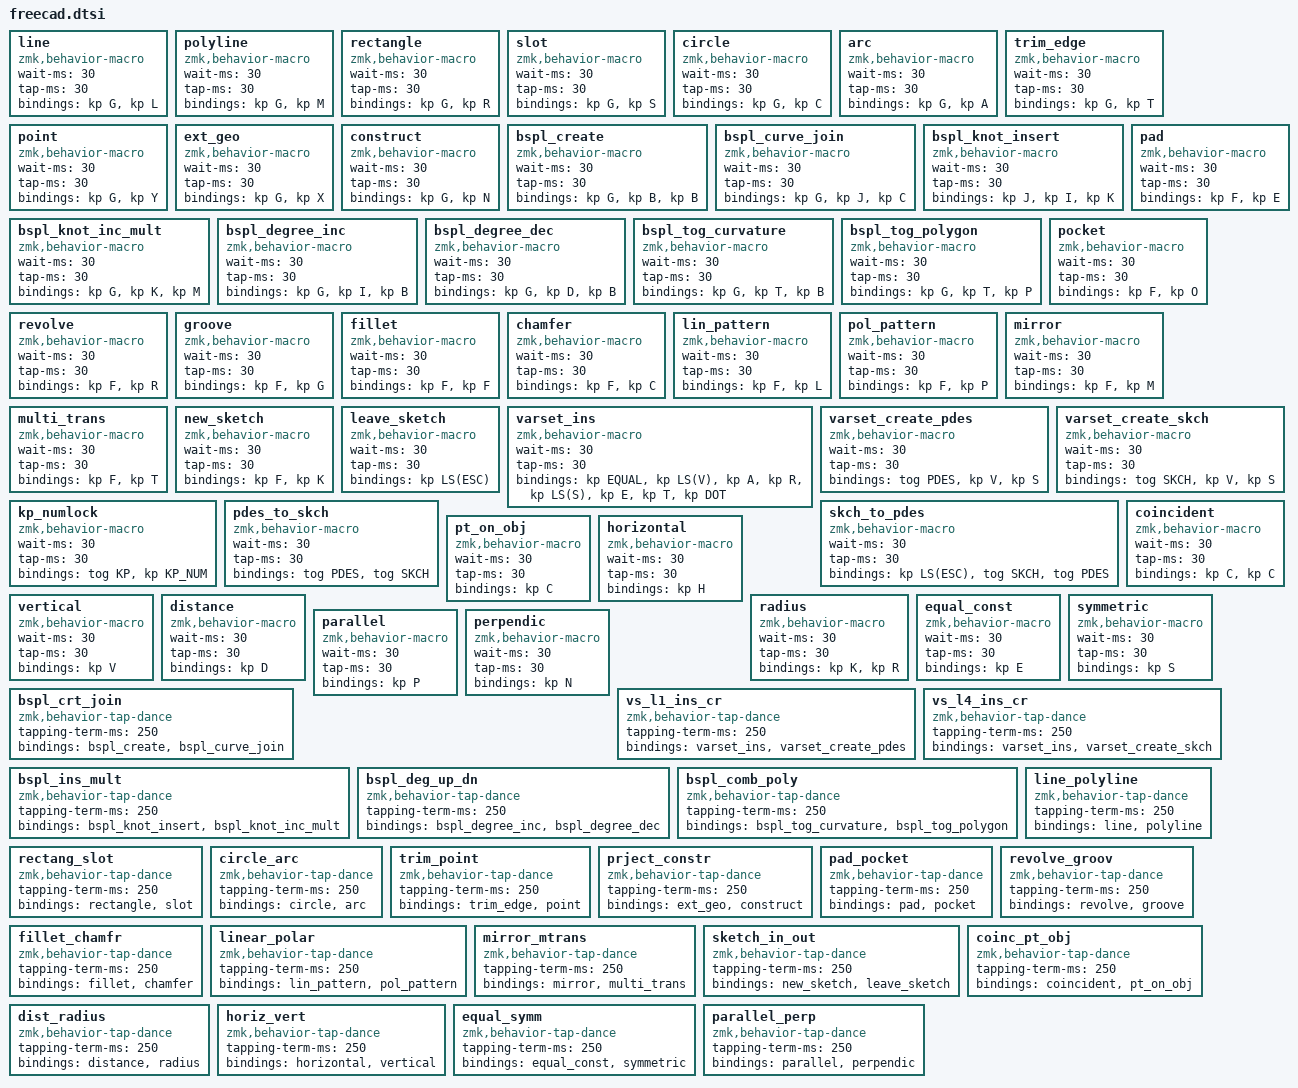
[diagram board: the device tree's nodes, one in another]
// ══════════════════════════════════════════════════════════════════════════════
// FREECAD MACROS & TAP-DANCES
// ══════════════════════════════════════════════════════════════════════════════

// --- MACROS: SKETCHER DOMAIN ---
line: line {
    compatible = "zmk,behavior-macro";
    #binding-cells = <0>;
    wait-ms = <30>;
    tap-ms = <30>;
    bindings = <&kp G>, <&kp L>;
};

polyline: polyline {
    compatible = "zmk,behavior-macro";
    #binding-cells = <0>;
    wait-ms = <30>;
    tap-ms = <30>;
    bindings = <&kp G>, <&kp M>;
};

rectangle: rectangle {
    compatible = "zmk,behavior-macro";
    #binding-cells = <0>;
    wait-ms = <30>;
    tap-ms = <30>;
    bindings = <&kp G>, <&kp R>;
};

slot: slot {
    compatible = "zmk,behavior-macro";
    #binding-cells = <0>;
    wait-ms = <30>;
    tap-ms = <30>;
    bindings = <&kp G>, <&kp S>;
};

circle: circle {
    compatible = "zmk,behavior-macro";
    #binding-cells = <0>;
    wait-ms = <30>;
    tap-ms = <30>;
    bindings = <&kp G>, <&kp C>;
};

arc: arc {
    compatible = "zmk,behavior-macro";
    #binding-cells = <0>;
    wait-ms = <30>;
    tap-ms = <30>;
    bindings = <&kp G>, <&kp A>;
};

trim_edge: trim_edge {
    compatible = "zmk,behavior-macro";
    #binding-cells = <0>;
    wait-ms = <30>;
    tap-ms = <30>;
    bindings = <&kp G>, <&kp T>;
};

point: point {
    compatible = "zmk,behavior-macro";
    #binding-cells = <0>;
    wait-ms = <30>;
    tap-ms = <30>;
    bindings = <&kp G>, <&kp Y>;
};

ext_geo: ext_geo {
    compatible = "zmk,behavior-macro";
    #binding-cells = <0>;
    wait-ms = <30>;
    tap-ms = <30>;
    bindings = <&kp G>, <&kp X>;
};

construct: construct {
    compatible = "zmk,behavior-macro";
    #binding-cells = <0>;
    wait-ms = <30>;
    tap-ms = <30>;
    bindings = <&kp G>, <&kp N>;
};

bspl_create: bspl_create {
    compatible = "zmk,behavior-macro";
    #binding-cells = <0>;
    wait-ms = <30>;
    tap-ms = <30>;
    bindings = <&kp G>, <&kp B>, <&kp B>;
};

bspl_curve_join: bspl_curve_join {
    compatible = "zmk,behavior-macro";
    #binding-cells = <0>;
    wait-ms = <30>;
    tap-ms = <30>;
    bindings = <&kp G>, <&kp J>, <&kp C>;
};

bspl_knot_insert: bspl_knot_insert {
    compatible = "zmk,behavior-macro";
    #binding-cells = <0>;
    wait-ms = <30>;
    tap-ms = <30>;
    bindings = <&kp J>, <&kp I>, <&kp K>;
};

bspl_knot_inc_mult: bspl_knot_inc_mult {
    compatible = "zmk,behavior-macro";
    #binding-cells = <0>;
    wait-ms = <30>;
    tap-ms = <30>;
    bindings = <&kp G>, <&kp K>, <&kp M>;
};

bspl_degree_inc: bspl_degree_inc {
    compatible = "zmk,behavior-macro";
    #binding-cells = <0>;
    wait-ms = <30>;
    tap-ms = <30>;
    bindings = <&kp G>, <&kp I>, <&kp B>;
};

bspl_degree_dec: bspl_degree_dec {
    compatible = "zmk,behavior-macro";
    #binding-cells = <0>;
    wait-ms = <30>;
    tap-ms = <30>;
    bindings = <&kp G>, <&kp D>, <&kp B>;
};

bspl_tog_curvature: bspl_tog_curvature {
    compatible = "zmk,behavior-macro";
    #binding-cells = <0>;
    wait-ms = <30>;
    tap-ms = <30>;
    bindings = <&kp G>, <&kp T>, <&kp B>;
};

bspl_tog_polygon: bspl_tog_polygon {
    compatible = "zmk,behavior-macro";
    #binding-cells = <0>;
    wait-ms = <30>;
    tap-ms = <30>;
    bindings = <&kp G>, <&kp T>, <&kp P>;
};


// --- MACROS: PART DESIGN DOMAIN ---
pad: pad {
    compatible = "zmk,behavior-macro";
    #binding-cells = <0>;
    wait-ms = <30>;
    tap-ms = <30>;
    bindings = <&kp F>, <&kp E>;
};

pocket: pocket {
    compatible = "zmk,behavior-macro";
    #binding-cells = <0>;
    wait-ms = <30>;
    tap-ms = <30>;
    bindings = <&kp F>, <&kp O>;
};

revolve: revolve {
    compatible = "zmk,behavior-macro";
    #binding-cells = <0>;
    wait-ms = <30>;
    tap-ms = <30>;
    bindings = <&kp F>, <&kp R>;
};

groove: groove {
    compatible = "zmk,behavior-macro";
    #binding-cells = <0>;
    wait-ms = <30>;
    tap-ms = <30>;
    bindings = <&kp F>, <&kp G>;
};

fillet: fillet {
    compatible = "zmk,behavior-macro";
    #binding-cells = <0>;
    wait-ms = <30>;
    tap-ms = <30>;
    bindings = <&kp F>, <&kp F>;
};

chamfer: chamfer {
    compatible = "zmk,behavior-macro";
    #binding-cells = <0>;
    wait-ms = <30>;
    tap-ms = <30>;
    bindings = <&kp F>, <&kp C>;
};

lin_pattern: lin_pattern {
    compatible = "zmk,behavior-macro";
    #binding-cells = <0>;
    wait-ms = <30>;
    tap-ms = <30>;
    bindings = <&kp F>, <&kp L>;
};

pol_pattern: pol_pattern {
    compatible = "zmk,behavior-macro";
    #binding-cells = <0>;
    wait-ms = <30>;
    tap-ms = <30>;
    bindings = <&kp F>, <&kp P>;
};

mirror: mirror {
    compatible = "zmk,behavior-macro";
    #binding-cells = <0>;
    wait-ms = <30>;
    tap-ms = <30>;
    bindings = <&kp F>, <&kp M>;
};

multi_trans: multi_trans {
    compatible = "zmk,behavior-macro";
    #binding-cells = <0>;
    wait-ms = <30>;
    tap-ms = <30>;
    bindings = <&kp F>, <&kp T>;
};

new_sketch: new_sketch {
    compatible = "zmk,behavior-macro";
    #binding-cells = <0>;
    wait-ms = <30>;
    tap-ms = <30>;
    bindings = <&kp F>, <&kp K>;
};

leave_sketch: leave_sketch {
    compatible = "zmk,behavior-macro";
    #binding-cells = <0>;
    wait-ms = <30>;
    tap-ms = <30>;
    bindings = <&kp LS(ESC)>;
};

// --- MACROS: VARSET ---
varset_ins: varset_ins {
    compatible = "zmk,behavior-macro";
    #binding-cells = <0>;
    wait-ms = <30>;
    tap-ms = <30>;
    bindings = <&kp EQUAL>, <&kp LS(V)>, <&kp A>, <&kp R>, <&kp LS(S)>, <&kp E>, <&kp T>, <&kp DOT>;
};

varset_create_pdes: varset_create_pdes {
    compatible = "zmk,behavior-macro";
    #binding-cells = <0>;
    wait-ms = <30>;
    tap-ms = <30>;
    bindings = <&tog PDES>, <&kp V>, <&kp S>;
};

varset_create_skch: varset_create_skch {
    compatible = "zmk,behavior-macro";
    #binding-cells = <0>;
    wait-ms = <30>;
    tap-ms = <30>;
    bindings = <&tog SKCH>, <&kp V>, <&kp S>;
};

// --- MACROS: LAYER NAVIGATION ---
kp_numlock: kp_numlock {
    compatible = "zmk,behavior-macro";
    #binding-cells = <0>;
    wait-ms = <30>;
    tap-ms = <30>;
    bindings = <&tog KP>, <&kp KP_NUM>;
};

skch_to_pdes: skch_to_pdes {
    compatible = "zmk,behavior-macro";
    #binding-cells = <0>;
    wait-ms = <30>;
    tap-ms = <30>;
    bindings = <&kp LS(ESC)>, <&tog SKCH>, <&tog PDES>;
};

pdes_to_skch: pdes_to_skch {
    compatible = "zmk,behavior-macro";
    #binding-cells = <0>;
    wait-ms = <30>;
    tap-ms = <30>;
    bindings = <&tog PDES>, <&tog SKCH>;
};

// --- MACROS: CONSTRAINTS DOMAIN ---
coincident: coincident {
    compatible = "zmk,behavior-macro";
    #binding-cells = <0>;
    wait-ms = <30>;
    tap-ms = <30>;
    bindings = <&kp C>, <&kp C>;
};

pt_on_obj: pt_on_obj {
    compatible = "zmk,behavior-macro";
    #binding-cells = <0>;
    wait-ms = <30>;
    tap-ms = <30>;
    bindings = <&kp C>;
};

horizontal: horizontal {
    compatible = "zmk,behavior-macro";
    #binding-cells = <0>;
    wait-ms = <30>;
    tap-ms = <30>;
    bindings = <&kp H>;
};

vertical: vertical {
    compatible = "zmk,behavior-macro";
    #binding-cells = <0>;
    wait-ms = <30>;
    tap-ms = <30>;
    bindings = <&kp V>;
};

distance: distance {
    compatible = "zmk,behavior-macro";
    #binding-cells = <0>;
    wait-ms = <30>;
    tap-ms = <30>;
    bindings = <&kp D>;
};

radius: radius {
    compatible = "zmk,behavior-macro";
    #binding-cells = <0>;
    wait-ms = <30>;
    tap-ms = <30>;
    bindings = <&kp K>, <&kp R>;
};

equal_const: equal_const {
    compatible = "zmk,behavior-macro";
    #binding-cells = <0>;
    wait-ms = <30>;
    tap-ms = <30>;
    bindings = <&kp E>;
};

symmetric: symmetric {
    compatible = "zmk,behavior-macro";
    #binding-cells = <0>;
    wait-ms = <30>;
    tap-ms = <30>;
    bindings = <&kp S>;
};

parallel: parallel {
    compatible = "zmk,behavior-macro";
    #binding-cells = <0>;
    wait-ms = <30>;
    tap-ms = <30>;
    bindings = <&kp P>;
};

perpendic: perpendic {
    compatible = "zmk,behavior-macro";
    #binding-cells = <0>;
    wait-ms = <30>;
    tap-ms = <30>;
    bindings = <&kp N>;
};


// ══════════════════════════════════════════════════════════════════════════════
// TAP-DANCE DEFINITIONS
// ══════════════════════════════════════════════════════════════════════════════

// --- TAP-DANCES: VARSET ---
vs_l1_ins_cr: vs_l1_ins_cr {
    compatible = "zmk,behavior-tap-dance";
    #binding-cells = <0>;
    tapping-term-ms = <250>;
    bindings = <&varset_ins>, <&varset_create_pdes>;
};

vs_l4_ins_cr: vs_l4_ins_cr {
    compatible = "zmk,behavior-tap-dance";
    #binding-cells = <0>;
    tapping-term-ms = <250>;
    bindings = <&varset_ins>, <&varset_create_skch>;
};

// --- TAP-DANCES: SKETCHER DOMAIN ---
bspl_crt_join: bspl_crt_join {
    compatible = "zmk,behavior-tap-dance";
    #binding-cells = <0>;
    tapping-term-ms = <250>;
    bindings = <&bspl_create>, <&bspl_curve_join>;
};

bspl_ins_mult: bspl_ins_mult {
    compatible = "zmk,behavior-tap-dance";
    #binding-cells = <0>;
    tapping-term-ms = <250>;
    bindings = <&bspl_knot_insert>, <&bspl_knot_inc_mult>;
};

bspl_deg_up_dn: bspl_deg_up_dn {
    compatible = "zmk,behavior-tap-dance";
    #binding-cells = <0>;
    tapping-term-ms = <250>;
    bindings = <&bspl_degree_inc>, <&bspl_degree_dec>;
};

bspl_comb_poly: bspl_comb_poly {
    compatible = "zmk,behavior-tap-dance";
    #binding-cells = <0>;
    tapping-term-ms = <250>;
    bindings = <&bspl_tog_curvature>, <&bspl_tog_polygon>;
};

line_polyline: line_polyline {
    compatible = "zmk,behavior-tap-dance";
    #binding-cells = <0>;
    tapping-term-ms = <250>;
    bindings = <&line>, <&polyline>;
};

rectang_slot: rectang_slot {
    compatible = "zmk,behavior-tap-dance";
    #binding-cells = <0>;
    tapping-term-ms = <250>;
    bindings = <&rectangle>, <&slot>;
};

circle_arc: circle_arc {
    compatible = "zmk,behavior-tap-dance";
    #binding-cells = <0>;
    tapping-term-ms = <250>;
    bindings = <&circle>, <&arc>;
};

trim_point: trim_point {
    compatible = "zmk,behavior-tap-dance";
    #binding-cells = <0>;
    tapping-term-ms = <250>;
    bindings = <&trim_edge>, <&point>;
};

prject_constr: prject_constr {
    compatible = "zmk,behavior-tap-dance";
    #binding-cells = <0>;
    tapping-term-ms = <250>;
    bindings = <&ext_geo>, <&construct>;
};

// --- TAP-DANCES: PART DESIGN DOMAIN ---
pad_pocket: pad_pocket {
    compatible = "zmk,behavior-tap-dance";
    #binding-cells = <0>;
    tapping-term-ms = <250>;
    bindings = <&pad>, <&pocket>;
};

revolve_groov: revolve_groov {
    compatible = "zmk,behavior-tap-dance";
    #binding-cells = <0>;
    tapping-term-ms = <250>;
    bindings = <&revolve>, <&groove>;
};

fillet_chamfr: fillet_chamfr {
    compatible = "zmk,behavior-tap-dance";
    #binding-cells = <0>;
    tapping-term-ms = <250>;
    bindings = <&fillet>, <&chamfer>;
};

linear_polar: linear_polar {
    compatible = "zmk,behavior-tap-dance";
    #binding-cells = <0>;
    tapping-term-ms = <250>;
    bindings = <&lin_pattern>, <&pol_pattern>;
};

mirror_mtrans: mirror_mtrans {
    compatible = "zmk,behavior-tap-dance";
    #binding-cells = <0>;
    tapping-term-ms = <250>;
    bindings = <&mirror>, <&multi_trans>;
};

sketch_in_out: sketch_in_out {
    compatible = "zmk,behavior-tap-dance";
    #binding-cells = <0>;
    tapping-term-ms = <250>;
    bindings = <&new_sketch>, <&leave_sketch>;
};

// --- TAP-DANCES: CONSTRAINTS DOMAIN ---
coinc_pt_obj: coinc_pt_obj {
    compatible = "zmk,behavior-tap-dance";
    #binding-cells = <0>;
    tapping-term-ms = <250>;
    bindings = <&coincident>, <&pt_on_obj>;
};

dist_radius: dist_radius {
    compatible = "zmk,behavior-tap-dance";
    #binding-cells = <0>;
    tapping-term-ms = <250>;
    bindings = <&distance>, <&radius>;
};

horiz_vert: horiz_vert {
    compatible = "zmk,behavior-tap-dance";
    #binding-cells = <0>;
    tapping-term-ms = <250>;
    bindings = <&horizontal>, <&vertical>;
};

equal_symm: equal_symm {
    compatible = "zmk,behavior-tap-dance";
    #binding-cells = <0>;
    tapping-term-ms = <250>;
    bindings = <&equal_const>, <&symmetric>;
};

parallel_perp: parallel_perp {
    compatible = "zmk,behavior-tap-dance";
    #binding-cells = <0>;
    tapping-term-ms = <250>;
    bindings = <&parallel>, <&perpendic>;
};
